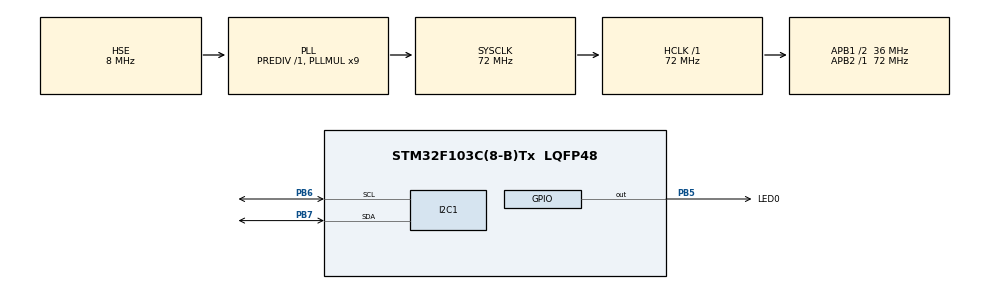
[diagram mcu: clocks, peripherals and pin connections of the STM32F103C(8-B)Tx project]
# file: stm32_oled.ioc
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Dma.I2C1_TX.0.Direction=DMA_MEMORY_TO_PERIPH
Dma.I2C1_TX.0.Instance=DMA1_Channel6
Dma.I2C1_TX.0.MemDataAlignment=DMA_MDATAALIGN_BYTE
Dma.I2C1_TX.0.MemInc=DMA_MINC_ENABLE
Dma.I2C1_TX.0.Mode=DMA_NORMAL
Dma.I2C1_TX.0.PeriphDataAlignment=DMA_PDATAALIGN_BYTE
Dma.I2C1_TX.0.PeriphInc=DMA_PINC_DISABLE
Dma.I2C1_TX.0.Priority=DMA_PRIORITY_LOW
Dma.Request0=I2C1_TX
FREERTOS.HEAP_NUMBER=4
FREERTOS.Tasks01=defaultTask,24,128,StartDefaultTask,Default,NULL,Static,defaultTaskBuffer,defaultTaskControlBlock;OledTask,24,256,StartTask_Oled,Default,NULL,Static,OledTaskBuffer,OledTaskControlBlock
FREERTOS.configTOTAL_HEAP_SIZE=512
Mcu.Family=STM32F1
Mcu.Name=STM32F103C(8-B)Tx
Mcu.Package=LQFP48
NVIC.DMA1_Channel6_IRQn=true\:5\:0\:false\:false\:true\:true\:false\:true\:true
NVIC.PriorityGroup=NVIC_PRIORITYGROUP_4
NVIC.TIM1_UP_IRQn=true\:15\:0\:false\:false\:true\:false\:false\:true\:true
NVIC.TimeBase=TIM1_UP_IRQn
NVIC.TimeBaseIP=TIM1
PA13.Mode=Serial_Wire
PA13.Signal=SYS_JTMS-SWDIO
PA14.Mode=Serial_Wire
PA14.Signal=SYS_JTCK-SWCLK
PB5.GPIO_Label=LED0
PB5.Signal=GPIO_Output
PB6.Mode=I2C
PB6.Signal=I2C1_SCL
PB7.Mode=I2C
PB7.Signal=I2C1_SDA
PD0-OSC_IN.Mode=HSE-External-Oscillator
PD0-OSC_IN.Signal=RCC_OSC_IN
PD1-OSC_OUT.Mode=HSE-External-Oscillator
PD1-OSC_OUT.Signal=RCC_OSC_OUT
ProjectManager.HeapSize=0x200
ProjectManager.StackSize=0x400
ProjectManager.TargetToolchain=CMake
RCC.AHBFreq_Value=72000000
RCC.APB1CLKDivider=RCC_HCLK_DIV2
RCC.APB1Freq_Value=36000000
RCC.APB1TimFreq_Value=72000000
RCC.APB2Freq_Value=72000000
RCC.APB2TimFreq_Value=72000000
RCC.HCLKFreq_Value=72000000
RCC.PLLMUL=RCC_PLL_MUL9
RCC.PLLSourceVirtual=RCC_PLLSOURCE_HSE
RCC.SYSCLKFreq_VALUE=72000000
RCC.SYSCLKSource=RCC_SYSCLKSOURCE_PLLCLK
RCC.USBFreq_Value=72000000
VP_FREERTOS_VS_CMSIS_V2.Mode=CMSIS_V2
VP_SYS_VS_tim1.Mode=TIM1
board=custom

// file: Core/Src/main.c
/* USER CODE BEGIN Header */
/**
  ******************************************************************************
  * @file           : main.c
  * @brief          : Main program body
  ******************************************************************************
  * @attention
  *
  * Copyright (c) 2026 STMicroelectronics.
  * All rights reserved.
  *
  * This software is licensed under terms that can be found in the LICENSE file
  * in the root directory of this software component.
  * If no LICENSE file comes with this software, it is provided AS-IS.
  *
  ******************************************************************************
  */
/* USER CODE END Header */
#include "main.h"
#include "cmsis_os.h"

/* USER CODE BEGIN Includes */
#include "ssd1306_tests.h"
/* USER CODE END Includes */

typedef StaticTask_t osStaticThreadDef_t;

I2C_HandleTypeDef hi2c1;
DMA_HandleTypeDef hdma_i2c1_tx;

/* Definitions for defaultTask */
osThreadId_t defaultTaskHandle;
uint32_t defaultTaskBuffer[ 128 ];
osStaticThreadDef_t defaultTaskControlBlock;
const osThreadAttr_t defaultTask_attributes = {
  .name = "defaultTask",
  .cb_mem = &defaultTaskControlBlock,
  .cb_size = sizeof(defaultTaskControlBlock),
  .stack_mem = &defaultTaskBuffer[0],
  .stack_size = sizeof(defaultTaskBuffer),
  .priority = (osPriority_t) osPriorityNormal,
};
/* Definitions for OledTask */
osThreadId_t OledTaskHandle;
uint32_t OledTaskBuffer[ 256 ];
osStaticThreadDef_t OledTaskControlBlock;
const osThreadAttr_t OledTask_attributes = {
  .name = "OledTask",
  .cb_mem = &OledTaskControlBlock,
  .cb_size = sizeof(OledTaskControlBlock),
  .stack_mem = &OledTaskBuffer[0],
  .stack_size = sizeof(OledTaskBuffer),
  .priority = (osPriority_t) osPriorityNormal,
};

void SystemClock_Config(void);
static void MX_GPIO_Init(void);
static void MX_DMA_Init(void);
static void MX_I2C1_Init(void);
void StartDefaultTask(void *argument);
void StartTask_Oled(void *argument);

int main(void)
{

  /* MCU Configuration--------------------------------------------------------*/

  /* Reset of all peripherals, Initializes the Flash interface and the Systick. */
  HAL_Init();

  /* Configure the system clock */
  SystemClock_Config();

  /* Initialize all configured peripherals */
  MX_GPIO_Init();
  MX_DMA_Init();
  MX_I2C1_Init();

  /* Init scheduler */
  osKernelInitialize();

  /* Create the thread(s) */
  /* creation of defaultTask */
  defaultTaskHandle = osThreadNew(StartDefaultTask, NULL, &defaultTask_attributes);

  /* creation of OledTask */
  OledTaskHandle = osThreadNew(StartTask_Oled, NULL, &OledTask_attributes);

  /* Start scheduler */
  osKernelStart();

  /* We should never get here as control is now taken by the scheduler */

  /* Infinite loop */
  while (1)
  {

  }
}

void SystemClock_Config(void)
{
  RCC_OscInitTypeDef RCC_OscInitStruct = {0};
  RCC_ClkInitTypeDef RCC_ClkInitStruct = {0};

  /** Initializes the RCC Oscillators according to the specified parameters
  * in the RCC_OscInitTypeDef structure.
  */
  RCC_OscInitStruct.OscillatorType = RCC_OSCILLATORTYPE_HSE;
  RCC_OscInitStruct.HSEState = RCC_HSE_ON;
  RCC_OscInitStruct.HSEPredivValue = RCC_HSE_PREDIV_DIV1;
  RCC_OscInitStruct.HSIState = RCC_HSI_ON;
  RCC_OscInitStruct.PLL.PLLState = RCC_PLL_ON;
  RCC_OscInitStruct.PLL.PLLSource = RCC_PLLSOURCE_HSE;
  RCC_OscInitStruct.PLL.PLLMUL = RCC_PLL_MUL9;
  if (HAL_RCC_OscConfig(&RCC_OscInitStruct) != HAL_OK)
  {
    Error_Handler();
  }

  /** Initializes the CPU, AHB and APB buses clocks
  */
  RCC_ClkInitStruct.ClockType = RCC_CLOCKTYPE_HCLK|RCC_CLOCKTYPE_SYSCLK
                              |RCC_CLOCKTYPE_PCLK1|RCC_CLOCKTYPE_PCLK2;
  RCC_ClkInitStruct.SYSCLKSource = RCC_SYSCLKSOURCE_PLLCLK;
  RCC_ClkInitStruct.AHBCLKDivider = RCC_SYSCLK_DIV1;
  RCC_ClkInitStruct.APB1CLKDivider = RCC_HCLK_DIV2;
  RCC_ClkInitStruct.APB2CLKDivider = RCC_HCLK_DIV1;

  if (HAL_RCC_ClockConfig(&RCC_ClkInitStruct, FLASH_LATENCY_2) != HAL_OK)
  {
    Error_Handler();
  }
}

static void MX_I2C1_Init(void)
{

  hi2c1.Instance = I2C1;
  hi2c1.Init.ClockSpeed = 100000;
  hi2c1.Init.DutyCycle = I2C_DUTYCYCLE_2;
  hi2c1.Init.OwnAddress1 = 0;
  hi2c1.Init.AddressingMode = I2C_ADDRESSINGMODE_7BIT;
  hi2c1.Init.DualAddressMode = I2C_DUALADDRESS_DISABLE;
  hi2c1.Init.OwnAddress2 = 0;
  hi2c1.Init.GeneralCallMode = I2C_GENERALCALL_DISABLE;
  hi2c1.Init.NoStretchMode = I2C_NOSTRETCH_DISABLE;
  if (HAL_I2C_Init(&hi2c1) != HAL_OK)
  {
    Error_Handler();
  }

}

static void MX_DMA_Init(void)
{

  /* DMA controller clock enable */
  __HAL_RCC_DMA1_CLK_ENABLE();

  /* DMA interrupt init */
  /* DMA1_Channel6_IRQn interrupt configuration */
  HAL_NVIC_SetPriority(DMA1_Channel6_IRQn, 5, 0);
  HAL_NVIC_EnableIRQ(DMA1_Channel6_IRQn);

}

static void MX_GPIO_Init(void)
{
  GPIO_InitTypeDef GPIO_InitStruct = {0};

  /* GPIO Ports Clock Enable */
  __HAL_RCC_GPIOD_CLK_ENABLE();
  __HAL_RCC_GPIOA_CLK_ENABLE();
  __HAL_RCC_GPIOB_CLK_ENABLE();

  /*Configure GPIO pin Output Level */
  HAL_GPIO_WritePin(LED0_GPIO_Port, LED0_Pin, GPIO_PIN_RESET);

  /*Configure GPIO pin : LED0_Pin */
  GPIO_InitStruct.Pin = LED0_Pin;
  GPIO_InitStruct.Mode = GPIO_MODE_OUTPUT_PP;
  GPIO_InitStruct.Pull = GPIO_NOPULL;
  GPIO_InitStruct.Speed = GPIO_SPEED_FREQ_LOW;
  HAL_GPIO_Init(LED0_GPIO_Port, &GPIO_InitStruct);

}

void StartDefaultTask(void *argument)
{
  /* USER CODE BEGIN 5 */

  /* Infinite loop */
  for(;;)
  {
        //timer_ticks++;

        //if (timer_ticks >= LED0_TOGGLE_PERIOD) {
        //    timer_ticks = 0;
            HAL_GPIO_TogglePin(LED0_GPIO_Port, LED0_Pin); // Zmiana stanu diody
        //}

    osDelay(1000);
  }
  /* USER CODE END 5 */
}

void StartTask_Oled(void *argument)
{
  /* USER CODE BEGIN StartTask_Oled */
  /* Infinite loop */
  for(;;)
  {
    ssd1306_TestAll();
    osDelay(1);
  }
  /* USER CODE END StartTask_Oled */
}

void HAL_TIM_PeriodElapsedCallback(TIM_HandleTypeDef *htim)
{
  if (htim->Instance == TIM1)
  {
    HAL_IncTick();
  }
}

void Error_Handler(void)
{
  __disable_irq();
  while (1)
  {
  }
}
